# LPC54S018M register map
Vendor: nxp.com; File version: 1.0
CPU: CM4 r0p1, little endian, MPU, FPU, VTOR, 3 interrupt priority bits
Registers are 32-bit, read-write, reset 0x0 unless marked. A register's access mark holds for its fields unless they carry their own. Offsets are from the block's base; [hi:lo] are bit positions; lines under a group give offsets from that group; {n}, {i} and the like mark numbered series.

## EMC — LPC54S60x/LPC5460x External Memory Controller (EMC)
Base 0x40081000
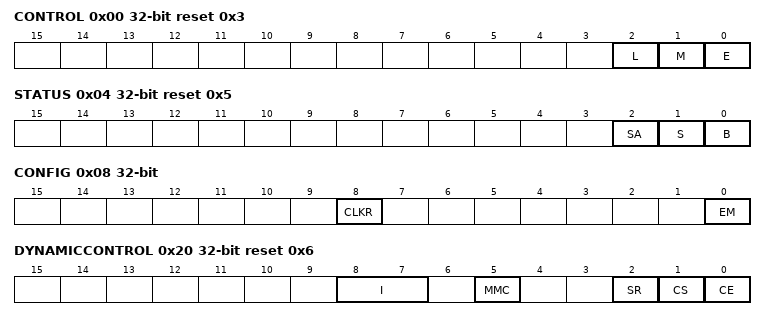
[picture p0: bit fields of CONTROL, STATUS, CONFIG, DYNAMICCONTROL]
0x00 CONTROL reset 0x3 — Controls operation of the memory controller
  [2] L — Low-power mode.
  [1] M — Address mirror.
  [0] E — EMC Enable.
0x04 STATUS ro reset 0x5 — Provides EMC status information
  [2] SA — Self-refresh acknowledge.
  [1] S — Write buffer status.
  [0] B — Busy.
0x08 CONFIG — Configures operation of the memory controller
  [8] CLKR — This bit must contain 0 for proper operation of the EMC.
  [0] EM — Endian mode.
0x20 DYNAMICCONTROL reset 0x6 — Controls dynamic memory operation
  [8:7] I — SDRAM initialization.
  [5] MMC — Memory clock control.
  [2] SR — Self-refresh request, EMCSREFREQ.
  [1] CS — Dynamic memory clock control.
  [0] CE — Dynamic memory clock enable.
0x24 DYNAMICREFRESH — Configures dynamic memory refresh
  [10:0] REFRESH — Refresh timer.
0x28 DYNAMICREADCONFIG — Configures dynamic memory read strategy
  [1:0] RD — Read data strategy.
0x30 DYNAMICRP reset 0xF — Precharge command period
  [3:0] TRP — Precharge command period.
0x34 DYNAMICRAS reset 0xF — Active to precharge command period
  [3:0] TRAS — Active to precharge command period.
0x38 DYNAMICSREX reset 0xF — Self-refresh exit time
  [3:0] TSREX — Self-refresh exit time.
0x3C DYNAMICAPR reset 0xF — Last-data-out to active command time
  [3:0] TAPR — Last-data-out to active command time.
0x40 DYNAMICDAL reset 0xF — Data-in to active command time
  [3:0] TDAL — Data-in to active command.
0x44 DYNAMICWR reset 0xF — Write recovery time
  [3:0] TWR — Write recovery time.
0x48 DYNAMICRC reset 0x1F — Selects the active to active command period
  [4:0] TRC — Active to active command period.
0x4C DYNAMICRFC reset 0x1F — Selects the auto-refresh period
  [4:0] TRFC — Auto-refresh period and auto-refresh to active command period.
0x50 DYNAMICXSR reset 0x1F — Time for exit self-refresh to active command
  [4:0] TXSR — Exit self-refresh to active command time.
0x54 DYNAMICRRD reset 0xF — Latency for active bank A to active bank B
  [3:0] TRRD — Active bank A to active bank B latency 0x0 - 0xE = n + 1 clock cycles.
0x58 DYNAMICMRD reset 0xF — Time for load mode register to active command
  [3:0] TMRD — Load mode register to active command time.
0x80 STATICEXTENDEDWAIT — Time for long static memory read and write transfers
  [9:0] EXTENDEDWAIT — Extended wait time out.
{0x100+0x20*i} DYNAMIC[{i}] (i=0..3) group
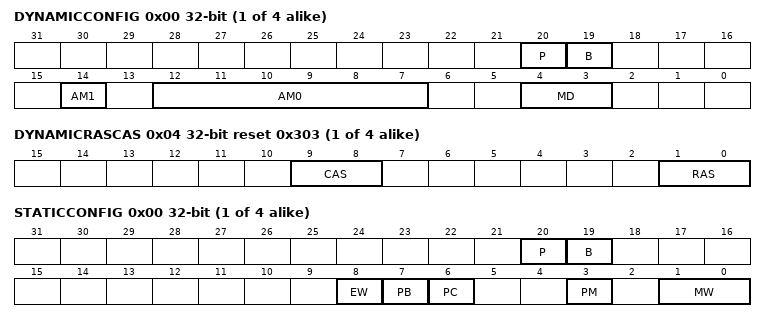
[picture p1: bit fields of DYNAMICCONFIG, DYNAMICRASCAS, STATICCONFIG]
  0x00 DYNAMICCONFIG — Configuration information for EMC_DYCSx
    [20] P — Write protect.
    [19] B — Buffer enable.
    [14] AM1 — See Table 933.
    [12:7] AM0 — See Table 933.
    [4:3] MD — Memory device.
  0x04 DYNAMICRASCAS reset 0x303 — RAS and CAS latencies for EMC_DYCSx
    [9:8] CAS — CAS latency.
    [1:0] RAS — RAS latency (active to read/write delay).
{0x200+0x20*i} STATIC[{i}] (i=0..3) group
  0x00 STATICCONFIG — Configuration for EMC_CSx
    [20] P — Write protect.
    [19] B — Buffer enable [2].
    [8] EW — Extended wait (EW) uses the EMCStaticExtendedWait register to time both the read and write transfers rather than the EMCStaticWaitRd and EMCStaticWaitWr registers.
    [7] PB — Byte lane state.
    [6] PC — Chip select polarity.
    [3] PM — Page mode.
    [1:0] MW — Memory width.
  0x04 STATICWAITWEN — Delay from EMC_CSx to write enable
    [3:0] WAITWEN — Wait write enable.
  0x08 STATICWAITOEN — Delay from EMC_CSx or address change, whichever is later, to output enable
    [3:0] WAITOEN — Wait output enable.
  0x0C STATICWAITRD reset 0x1F — Delay from EMC_CSx to a read access
    [4:0] WAITRD
  0x10 STATICWAITPAGE reset 0x1F — Delay for asynchronous page mode sequential accesses for EMC_CSx
    [4:0] WAITPAGE — Asynchronous page mode read after the first read wait states.
  0x14 STATICWAITWR reset 0x1F — Delay from EMC_CSx to a write access
    [4:0] WAITWR — Write wait states.
  0x18 STATICWAITTURN reset 0xF — Number of bus turnaround cycles EMC_CSx
    [3:0] WAITTURN — Bus turn-around cycles.
